VERSION ""

NS_ :

BS_:

BU_: STEERING SPEED

BO_ 688 STEERING_ANGLE: 8 STEERING
 SG_ STEERING_ANGLE_angle : 0|16@1- (0.1,0) [0|0] "" STEERING
 SG_ STEERING_ANGLE_reserved : 16|48@1+ (1,0) [0|0] "" STEERING

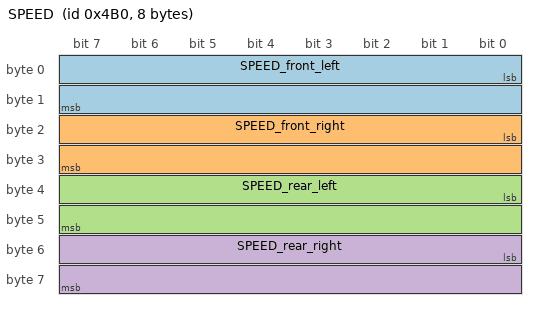
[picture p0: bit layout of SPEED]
BO_ 1200 SPEED: 8 SPEED
 SG_ SPEED_front_left : 0|16@1- (0.02,0) [0|0] "" SPEED
 SG_ SPEED_front_right : 16|16@1- (0.02,0) [0|0] "" SPEED
 SG_ SPEED_rear_left : 32|16@1- (0.02,0) [0|0] "" SPEED
 SG_ SPEED_rear_right : 48|16@1- (0.02,0) [0|0] "" SPEED
